VERSION ""

NS_ :

BS_:

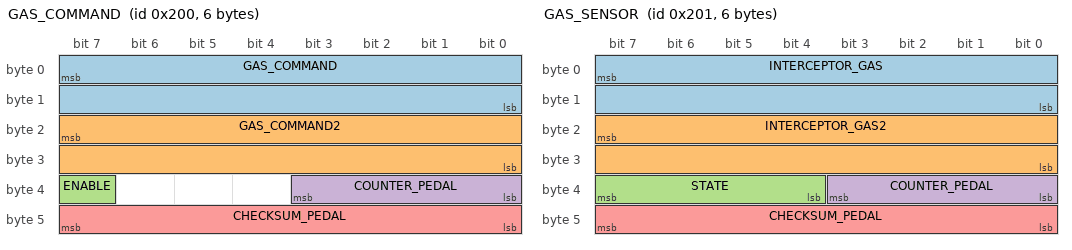
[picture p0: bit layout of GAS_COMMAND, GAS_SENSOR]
BO_ 512 GAS_COMMAND: 6 EON
 SG_ GAS_COMMAND : 7|16@0+ (0.253984064,-83.3) [0|1] "" INTERCEPTOR
 SG_ GAS_COMMAND2 : 23|16@0+ (0.126992032,-83.3) [0|1] "" INTERCEPTOR
 SG_ ENABLE : 39|1@0+ (1,0) [0|1] "" INTERCEPTOR
 SG_ COUNTER_PEDAL : 35|4@0+ (1,0) [0|15] "" INTERCEPTOR
 SG_ CHECKSUM_PEDAL : 47|8@0+ (1,0) [0|255] "" INTERCEPTOR

BO_ 513 GAS_SENSOR: 6 INTERCEPTOR
 SG_ INTERCEPTOR_GAS : 7|16@0+ (1,0) [0|1] "" EON
 SG_ INTERCEPTOR_GAS2 : 23|16@0+ (1,0) [0|1] "" EON
 SG_ STATE : 39|4@0+ (1,0) [0|15] "" EON
 SG_ COUNTER_PEDAL : 35|4@0+ (1,0) [0|15] "" EON
 SG_ CHECKSUM_PEDAL : 47|8@0+ (1,0) [0|255] "" EON

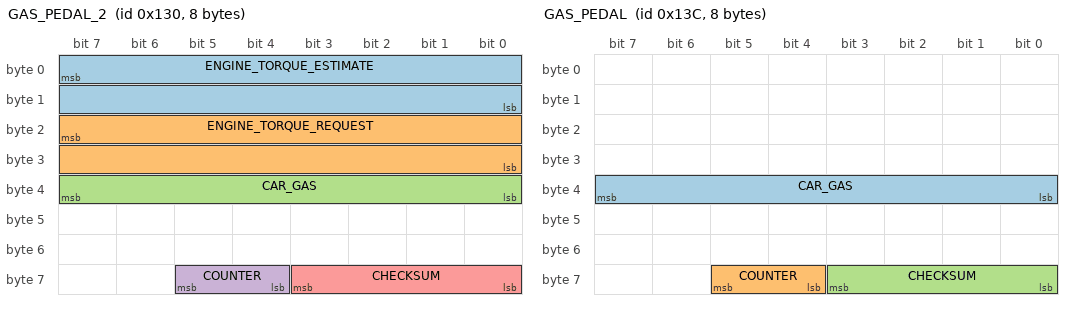
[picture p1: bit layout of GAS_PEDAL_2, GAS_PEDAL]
BO_ 304 GAS_PEDAL_2: 8 PCM
 SG_ ENGINE_TORQUE_ESTIMATE : 7|16@0- (1,0) [-1000|1000] "Nm" EON
 SG_ ENGINE_TORQUE_REQUEST : 23|16@0- (1,0) [-1000|1000] "Nm" EON
 SG_ CAR_GAS : 39|8@0+ (1,0) [0|255] "" EON
 SG_ COUNTER : 61|2@0+ (1,0) [0|3] "" EON
 SG_ CHECKSUM : 59|4@0+ (1,0) [0|15] "" EON

BO_ 316 GAS_PEDAL: 8 PCM
 SG_ CAR_GAS : 39|8@0+ (1,0) [0|255] "" EON
 SG_ COUNTER : 61|2@0+ (1,0) [0|3] "" EON
 SG_ CHECKSUM : 59|4@0+ (1,0) [0|15] "" EON

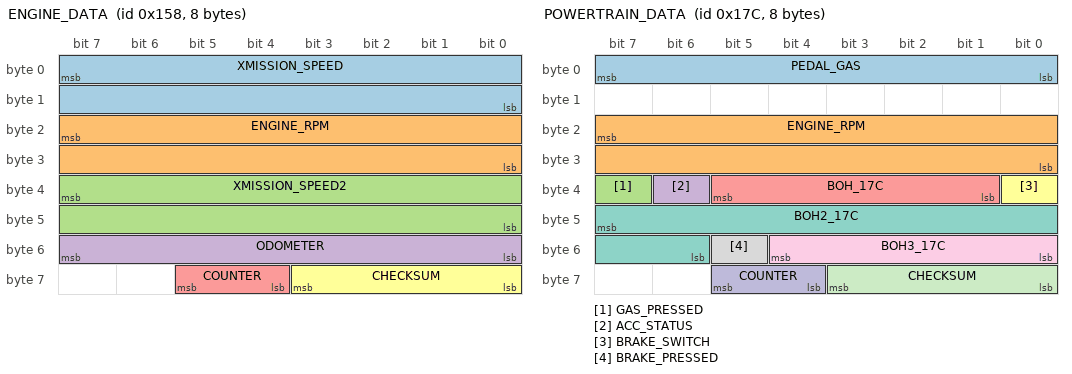
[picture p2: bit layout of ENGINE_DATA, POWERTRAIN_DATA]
BO_ 344 ENGINE_DATA: 8 PCM
 SG_ XMISSION_SPEED : 7|16@0+ (0.01,0) [0|250] "kph" EON
 SG_ ENGINE_RPM : 23|16@0+ (1,0) [0|15000] "rpm" EON
 SG_ XMISSION_SPEED2 : 39|16@0+ (0.01,0) [0|250] "kph" EON
 SG_ ODOMETER : 55|8@0+ (10,0) [0|2550] "m" XXX
 SG_ COUNTER : 61|2@0+ (1,0) [0|3] "" EON
 SG_ CHECKSUM : 59|4@0+ (1,0) [0|15] "" EON

BO_ 380 POWERTRAIN_DATA: 8 PCM
 SG_ PEDAL_GAS : 7|8@0+ (1,0) [0|255] "" EON
 SG_ ENGINE_RPM : 23|16@0+ (1,0) [0|15000] "rpm" EON
 SG_ GAS_PRESSED : 39|1@0+ (1,0) [0|1] "" EON
 SG_ ACC_STATUS : 38|1@0+ (1,0) [0|1] "" EON
 SG_ BOH_17C : 37|5@0+ (1,0) [0|1] "" EON
 SG_ BRAKE_SWITCH : 32|1@0+ (1,0) [0|1] "" EON
 SG_ BOH2_17C : 47|10@0+ (1,0) [0|1] "" EON
 SG_ BRAKE_PRESSED : 53|1@0+ (1,0) [0|1] "" EON
 SG_ BOH3_17C : 52|5@0+ (1,0) [0|1] "" EON
 SG_ COUNTER : 61|2@0+ (1,0) [0|3] "" EON
 SG_ CHECKSUM : 59|4@0+ (1,0) [0|15] "" EON

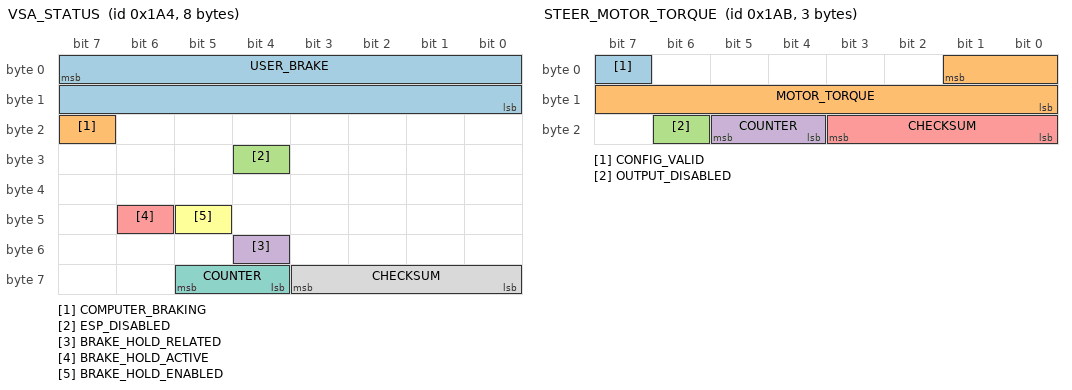
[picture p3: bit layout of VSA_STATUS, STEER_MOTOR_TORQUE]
BO_ 420 VSA_STATUS: 8 VSA
 SG_ USER_BRAKE : 7|16@0+ (0.015625,-1.609375) [0|1000] "" EON
 SG_ COMPUTER_BRAKING : 23|1@0+ (1,0) [0|1] "" EON
 SG_ ESP_DISABLED : 28|1@0+ (1,0) [0|1] "" EON
 SG_ BRAKE_HOLD_RELATED : 52|1@0+ (1,0) [0|1] "" XXX
 SG_ BRAKE_HOLD_ACTIVE : 46|1@0+ (1,0) [0|1] "" EON
 SG_ BRAKE_HOLD_ENABLED : 45|1@0+ (1,0) [0|1] "" EON
 SG_ COUNTER : 61|2@0+ (1,0) [0|3] "" EON
 SG_ CHECKSUM : 59|4@0+ (1,0) [0|15] "" EON

BO_ 427 STEER_MOTOR_TORQUE: 3 EPS
 SG_ CONFIG_VALID : 7|1@0+ (1,0) [0|1] "" EON
 SG_ MOTOR_TORQUE : 1|10@0+ (1,0) [0|256] "" EON
 SG_ OUTPUT_DISABLED : 22|1@0+ (1,0) [0|1] "" EON
 SG_ COUNTER : 21|2@0+ (1,0) [0|3] "" EON
 SG_ CHECKSUM : 19|4@0+ (1,0) [0|15] "" EON

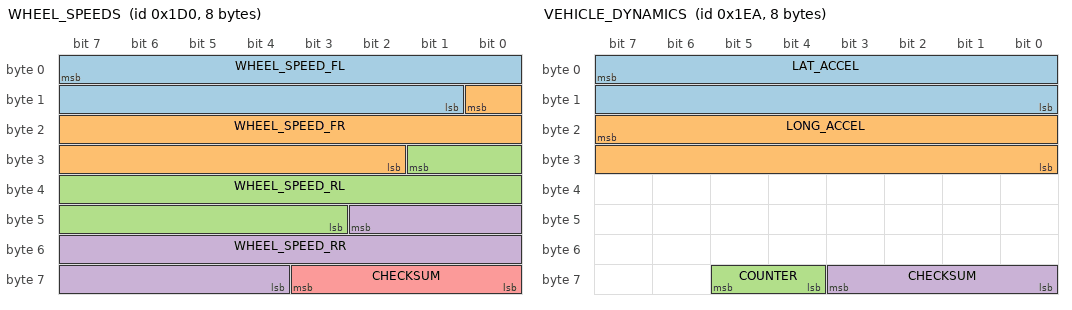
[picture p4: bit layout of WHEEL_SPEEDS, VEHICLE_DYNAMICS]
BO_ 464 WHEEL_SPEEDS: 8 VSA
 SG_ WHEEL_SPEED_FL : 7|15@0+ (0.01,0) [0|250] "kph" EON
 SG_ WHEEL_SPEED_FR : 8|15@0+ (0.01,0) [0|250] "kph" EON
 SG_ WHEEL_SPEED_RL : 25|15@0+ (0.01,0) [0|250] "kph" EON
 SG_ WHEEL_SPEED_RR : 42|15@0+ (0.01,0) [0|250] "kph" EON
 SG_ CHECKSUM : 59|4@0+ (1,0) [0|3] "" EON

BO_ 490 VEHICLE_DYNAMICS: 8 VSA
 SG_ LAT_ACCEL : 7|16@0- (0.0015,0) [-20|20] "m/s2" EON
 SG_ LONG_ACCEL : 23|16@0- (0.0015,0) [-20|20] "m/s2" EON
 SG_ COUNTER : 61|2@0+ (1,0) [0|3] "" EON
 SG_ CHECKSUM : 59|4@0+ (1,0) [0|3] "" EON

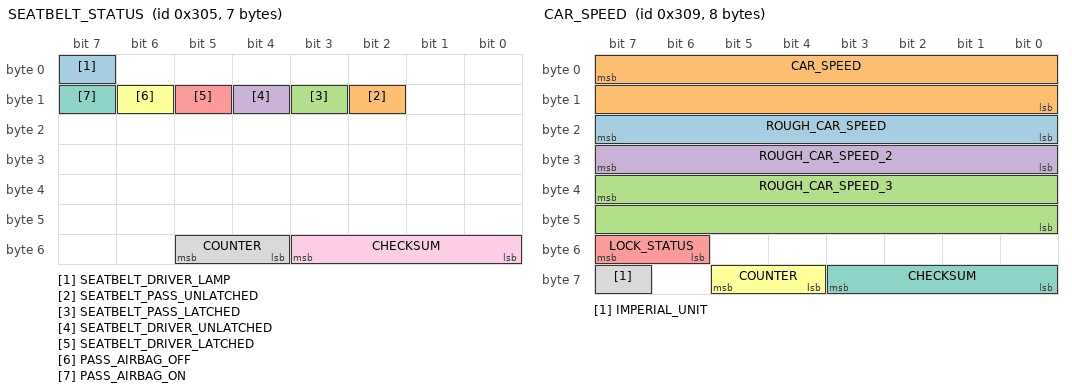
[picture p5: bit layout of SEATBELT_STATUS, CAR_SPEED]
BO_ 773 SEATBELT_STATUS: 7 BDY
 SG_ SEATBELT_DRIVER_LAMP : 7|1@0+ (1,0) [0|1] "" EON
 SG_ SEATBELT_PASS_UNLATCHED : 10|1@0+ (1,0) [0|1] "" EON
 SG_ SEATBELT_PASS_LATCHED : 11|1@0+ (1,0) [0|1] "" EON
 SG_ SEATBELT_DRIVER_UNLATCHED : 12|1@0+ (1,0) [0|1] "" EON
 SG_ SEATBELT_DRIVER_LATCHED : 13|1@0+ (1,0) [0|1] "" EON
 SG_ PASS_AIRBAG_OFF : 14|1@0+ (1,0) [0|1] "" EON
 SG_ PASS_AIRBAG_ON : 15|1@0+ (1,0) [0|1] "" EON
 SG_ COUNTER : 53|2@0+ (1,0) [0|3] "" EON
 SG_ CHECKSUM : 51|4@0+ (1,0) [0|3] "" EON

BO_ 777 CAR_SPEED: 8 PCM
 SG_ ROUGH_CAR_SPEED : 23|8@0+ (1,0) [0|255] "mph" XXX
 SG_ CAR_SPEED : 7|16@0+ (0.01,0) [0|65535] "kph" XXX
 SG_ ROUGH_CAR_SPEED_3 : 39|16@0+ (0.01,0) [0|65535] "kph" XXX
 SG_ ROUGH_CAR_SPEED_2 : 31|8@0+ (1,0) [0|255] "mph" XXX
 SG_ LOCK_STATUS : 55|2@0+ (1,0) [0|255] "" XXX
 SG_ COUNTER : 61|2@0+ (1,0) [0|3] "" XXX
 SG_ CHECKSUM : 59|4@0+ (1,0) [0|15] "" XXX
 SG_ IMPERIAL_UNIT : 63|1@0+ (1,0) [0|1] "" XXX

BO_ 780 ACC_HUD: 8 ADAS
 SG_ PCM_SPEED : 7|16@0+ (0.01,0) [0|250] "kph" BDY
 SG_ PCM_GAS : 23|8@0+ (1,0) [0|127] "" BDY
 SG_ CRUISE_SPEED : 31|8@0+ (1,0) [0|255] "kph" BDY
 SG_ DTC_MODE : 39|1@0+ (1,0) [0|1] "" BDY
 SG_ BOH : 38|1@0+ (1,0) [0|1] "" BDY
 SG_ ACC_PROBLEM : 37|1@0+ (1,0) [0|1] "" BDY
 SG_ FCM_OFF : 35|1@0+ (1,0) [0|1] "" BDY
 SG_ FCM_OFF_2 : 36|1@0+ (1,0) [0|1] "" BDY
 SG_ FCM_PROBLEM : 34|1@0+ (1,0) [0|1] "" BDY
 SG_ RADAR_OBSTRUCTED : 33|1@0+ (1,0) [0|1] "" BDY
 SG_ ENABLE_MINI_CAR : 32|1@0+ (1,0) [0|1] "" BDY
 SG_ HUD_DISTANCE : 47|2@0+ (1,0) [0|3] "" BDY
 SG_ HUD_LEAD : 45|2@0+ (1,0) [0|3] "" BDY
 SG_ BOH_3 : 43|1@0+ (1,0) [0|3] "" BDY
 SG_ BOH_4 : 42|1@0+ (1,0) [0|3] "" BDY
 SG_ BOH_5 : 41|1@0+ (1,0) [0|3] "" BDY
 SG_ CRUISE_CONTROL_LABEL : 40|1@0+ (1,0) [0|3] "" BDY
 SG_ SET_ME_X01_2 : 55|1@0+ (1,0) [0|1] "" BDY
 SG_ IMPERIAL_UNIT : 54|1@0+ (1,0) [0|1] "" BDY
 SG_ ACC_ON : 52|1@0+ (1,0) [0|1] "" BDY
 SG_ CHIME : 51|3@0+ (1,0) [0|1] "" BDY
 SG_ SET_ME_X01 : 48|1@0+ (1,0) [0|1] "" BDY
 SG_ ICONS : 63|2@0+ (1,0) [0|1] "" BDY
 SG_ COUNTER : 61|2@0+ (1,0) [0|3] "" BDY
 SG_ CHECKSUM : 59|4@0+ (1,0) [0|3] "" BDY

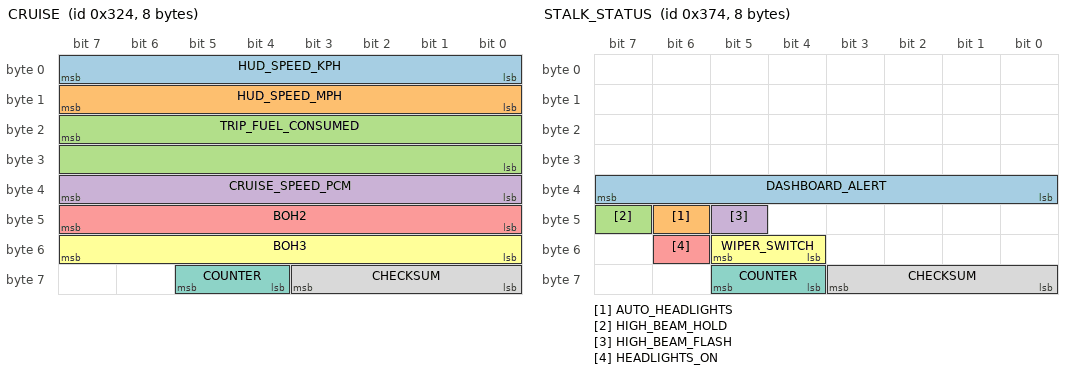
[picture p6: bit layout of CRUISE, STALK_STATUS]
BO_ 804 CRUISE: 8 PCM
 SG_ HUD_SPEED_KPH : 7|8@0+ (1,0) [0|255] "kph" EON
 SG_ HUD_SPEED_MPH : 15|8@0+ (1,0) [0|255] "mph" EON
 SG_ TRIP_FUEL_CONSUMED : 23|16@0+ (1,0) [0|255] "" EON
 SG_ CRUISE_SPEED_PCM : 39|8@0+ (1,0) [0|255] "" EON
 SG_ BOH2 : 47|8@0- (1,0) [0|255] "" EON
 SG_ BOH3 : 55|8@0+ (1,0) [0|255] "" EON
 SG_ COUNTER : 61|2@0+ (1,0) [0|3] "" EON
 SG_ CHECKSUM : 59|4@0+ (1,0) [0|15] "" EON

BO_ 884 STALK_STATUS: 8 XXX
 SG_ DASHBOARD_ALERT : 39|8@0+ (1,0) [0|255] "" EON
 SG_ AUTO_HEADLIGHTS : 46|1@0+ (1,0) [0|1] "" EON
 SG_ HIGH_BEAM_HOLD : 47|1@0+ (1,0) [0|1] "" EON
 SG_ HIGH_BEAM_FLASH : 45|1@0+ (1,0) [0|1] "" EON
 SG_ HEADLIGHTS_ON : 54|1@0+ (1,0) [0|1] "" EON
 SG_ WIPER_SWITCH : 53|2@0+ (1,0) [0|3] "" XXX
 SG_ COUNTER : 61|2@0+ (1,0) [0|3] "" EON
 SG_ CHECKSUM : 59|4@0+ (1,0) [0|15] "" EON

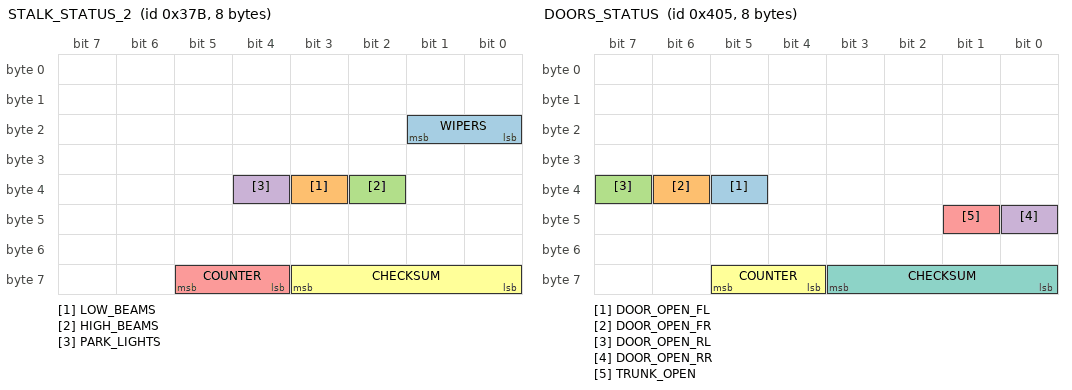
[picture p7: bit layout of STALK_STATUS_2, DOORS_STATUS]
BO_ 891 STALK_STATUS_2: 8 XXX
 SG_ WIPERS : 17|2@0+ (1,0) [0|3] "" EON
 SG_ LOW_BEAMS : 35|1@0+ (1,0) [0|1] "" XXX
 SG_ HIGH_BEAMS : 34|1@0+ (1,0) [0|1] "" XXX
 SG_ PARK_LIGHTS : 36|1@0+ (1,0) [0|1] "" XXX
 SG_ COUNTER : 61|2@0+ (1,0) [0|3] "" EON
 SG_ CHECKSUM : 59|4@0+ (1,0) [0|15] "" EON

BO_ 1029 DOORS_STATUS: 8 BDY
 SG_ DOOR_OPEN_FL : 37|1@0+ (1,0) [0|1] "" EON
 SG_ DOOR_OPEN_FR : 38|1@0+ (1,0) [0|1] "" EON
 SG_ DOOR_OPEN_RL : 39|1@0+ (1,0) [0|1] "" EON
 SG_ DOOR_OPEN_RR : 40|1@0+ (1,0) [0|1] "" EON
 SG_ TRUNK_OPEN : 41|1@0+ (1,0) [0|1] "" EON
 SG_ COUNTER : 61|2@0+ (1,0) [0|3] "" EON
 SG_ CHECKSUM : 59|4@0+ (1,0) [0|15] "" EON

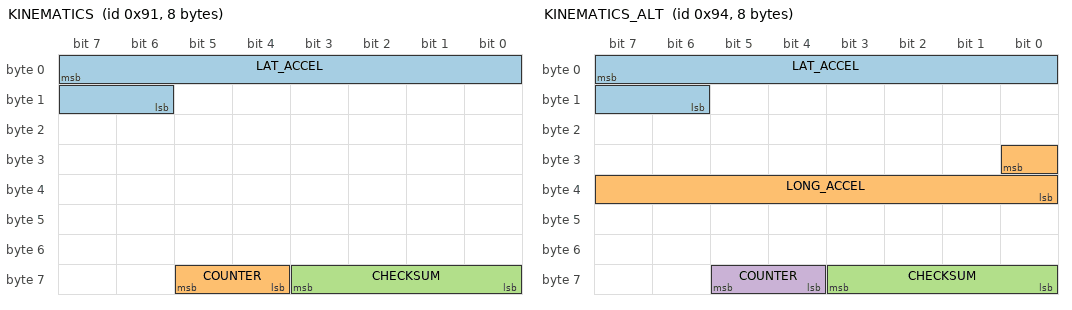
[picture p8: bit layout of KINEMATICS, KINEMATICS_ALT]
BO_ 145 KINEMATICS: 8 XXX
 SG_ LAT_ACCEL : 7|10@0+ (0.02,-512) [-20|20] "m/s2" EON
 SG_ COUNTER : 61|2@0+ (1,0) [0|3] "" EON
 SG_ CHECKSUM : 59|4@0+ (1,0) [0|3] "" EON

BO_ 148 KINEMATICS_ALT: 8 XXX
 SG_ LAT_ACCEL : 7|10@0+ (0.02,-512) [-20|20] "m/s2" EON
 SG_ LONG_ACCEL : 24|9@0- (-0.02,0) [-20|20] "m/s2" EON
 SG_ CHECKSUM : 59|4@0+ (1,0) [0|3] "" EON
 SG_ COUNTER : 61|2@0+ (1,0) [0|3] "" EON

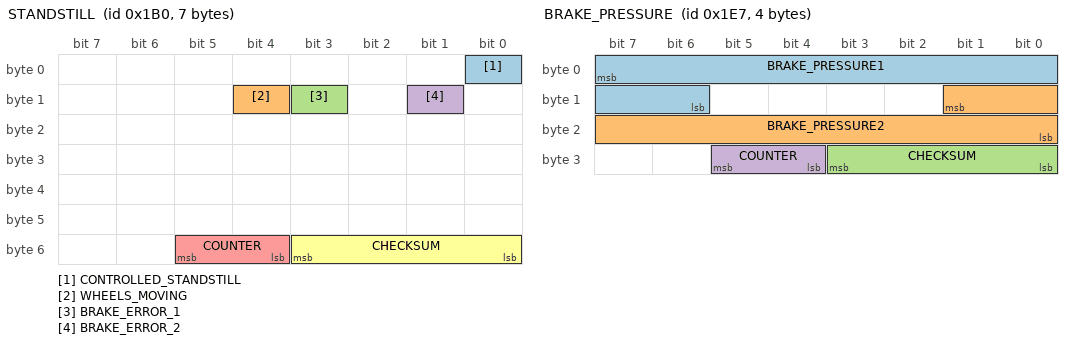
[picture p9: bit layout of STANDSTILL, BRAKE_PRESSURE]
BO_ 432 STANDSTILL: 7 VSA
 SG_ CONTROLLED_STANDSTILL : 0|1@0+ (1,0) [0|1] "" EON
 SG_ WHEELS_MOVING : 12|1@0+ (1,0) [0|1] "" EON
 SG_ BRAKE_ERROR_1 : 11|1@0+ (1,0) [0|1] "" EON
 SG_ BRAKE_ERROR_2 : 9|1@0+ (1,0) [0|1] "" EON
 SG_ COUNTER : 53|2@0+ (1,0) [0|3] "" EON
 SG_ CHECKSUM : 51|4@0+ (1,0) [0|3] "" EON

BO_ 487 BRAKE_PRESSURE: 4 VSA
 SG_ BRAKE_PRESSURE1 : 7|10@0+ (0.015625,-103) [0|1000] "" EON
 SG_ BRAKE_PRESSURE2 : 9|10@0+ (0.015625,-103) [0|1000] "" EON
 SG_ CHECKSUM : 27|4@0+ (1,0) [0|15] "" EON
 SG_ COUNTER : 29|2@0+ (1,0) [0|3] "" EON

BO_ 506 BRAKE_COMMAND: 8 ADAS
 SG_ COMPUTER_BRAKE : 7|10@0+ (1,0) [0|1] "" EBCM
 SG_ BRAKE_PUMP_REQUEST : 8|1@0+ (1,0) [0|1] "" EBCM
 SG_ BRAKE_PUMP_REQUEST_ALT : 11|1@0+ (1,0) [0|1] "" EBCM
 SG_ SET_ME_X00 : 23|3@0+ (1,0) [0|1] "" EBCM
 SG_ CRUISE_OVERRIDE : 20|1@0+ (1,0) [0|1] "" EBCM
 SG_ SET_ME_X00_2 : 19|1@0+ (1,0) [0|1] "" EBCM
 SG_ CRUISE_FAULT_CMD : 18|1@0+ (1,0) [0|1] "" EBCM
 SG_ CRUISE_CANCEL_CMD : 17|1@0+ (1,0) [0|1] "" EBCM
 SG_ COMPUTER_BRAKE_REQUEST : 16|1@0+ (1,0) [0|1] "" EBCM
 SG_ SET_ME_1 : 31|1@0+ (1,0) [0|1] "" EBCM
 SG_ AEB_REQ_1 : 29|1@0+ (1,0) [0|1] "" XXX
 SG_ AEB_REQ_2 : 26|3@0+ (1,0) [0|7] "" XXX
 SG_ BRAKE_LIGHTS : 39|1@0+ (1,0) [0|1] "" EBCM
 SG_ CRUISE_STATES : 38|7@0+ (1,0) [0|1] "" EBCM
 SG_ CHIME : 47|3@0+ (1,0) [0|7] "" EBCM
 SG_ SET_ME_X00_3 : 44|1@0+ (1,0) [0|1] "" EBCM
 SG_ FCW : 43|2@0+ (1,0) [0|3] "" EBCM
 SG_ AEB_STATUS : 41|2@0+ (1,0) [0|3] "" XXX
 SG_ COMPUTER_BRAKE_ALT : 55|10@0+ (1,0) [0|0] "" EBCM
 SG_ COUNTER : 61|2@0+ (1,0) [0|3] "" EBCM
 SG_ CHECKSUM : 59|4@0+ (1,0) [0|15] "" EBCM

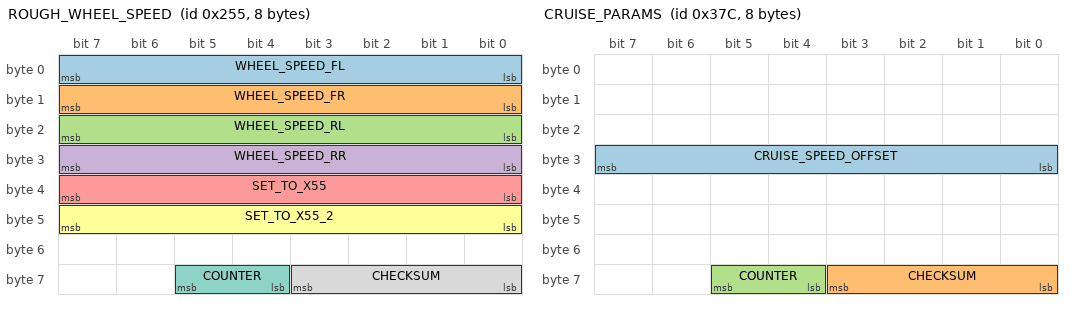
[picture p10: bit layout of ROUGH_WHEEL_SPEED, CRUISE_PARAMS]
BO_ 597 ROUGH_WHEEL_SPEED: 8 VSA
 SG_ WHEEL_SPEED_FL : 7|8@0+ (1,0) [0|255] "mph" EON
 SG_ WHEEL_SPEED_FR : 15|8@0+ (1,0) [0|255] "mph" EON
 SG_ WHEEL_SPEED_RL : 23|8@0+ (1,0) [0|255] "mph" EON
 SG_ WHEEL_SPEED_RR : 31|8@0+ (1,0) [0|255] "mph" EON
 SG_ SET_TO_X55 : 39|8@0+ (1,0) [0|255] "" EON
 SG_ SET_TO_X55_2 : 47|8@0+ (1,0) [0|255] "" EON
 SG_ COUNTER : 61|2@0+ (1,0) [0|3] "" EON
 SG_ CHECKSUM : 59|4@0+ (1,0) [0|15] "" EON

BO_ 829 LKAS_HUD: 5 ADAS
 SG_ CAM_TEMP_HIGH : 7|1@0+ (1,0) [0|255] "" BDY
 SG_ SET_ME_X41 : 6|7@0+ (1,0) [0|127] "" BDY
 SG_ BOH : 6|7@0+ (1,0) [0|127] "" BDY
 SG_ DASHED_LANES : 14|1@0+ (1,0) [0|1] "" BDY
 SG_ DTC : 13|1@0+ (1,0) [0|1] "" BDY
 SG_ LKAS_PROBLEM : 12|1@0+ (1,0) [0|1] "" BDY
 SG_ LKAS_OFF : 11|1@0+ (1,0) [0|1] "" BDY
 SG_ SOLID_LANES : 10|1@0+ (1,0) [0|1] "" BDY
 SG_ LDW_RIGHT : 9|1@0+ (1,0) [0|1] "" BDY
 SG_ STEERING_REQUIRED : 8|1@0+ (1,0) [0|1] "" BDY
 SG_ BOH_2 : 23|2@0+ (1,0) [0|4] "" BDY
 SG_ LDW_PROBLEM : 21|1@0+ (1,0) [0|1] "" BDY
 SG_ BEEP : 17|2@0+ (1,0) [0|1] "" BDY
 SG_ LDW_ON : 28|1@0+ (1,0) [0|1] "" BDY
 SG_ LDW_OFF : 27|1@0+ (1,0) [0|1] "" BDY
 SG_ CLEAN_WINDSHIELD : 26|1@0+ (1,0) [0|1] "" BDY
 SG_ SET_ME_X48 : 31|8@0+ (1,0) [0|255] "" BDY
 SG_ COUNTER : 37|2@0+ (1,0) [0|3] "" BDY
 SG_ CHECKSUM : 35|4@0+ (1,0) [0|15] "" BDY

BO_ 892 CRUISE_PARAMS: 8 PCM
 SG_ CRUISE_SPEED_OFFSET : 31|8@0- (0.1,0) [-128|127] "kph" EON
 SG_ CHECKSUM : 59|4@0+ (1,0) [0|3] "" EON
 SG_ COUNTER : 61|2@0+ (1,0) [0|3] "" EON

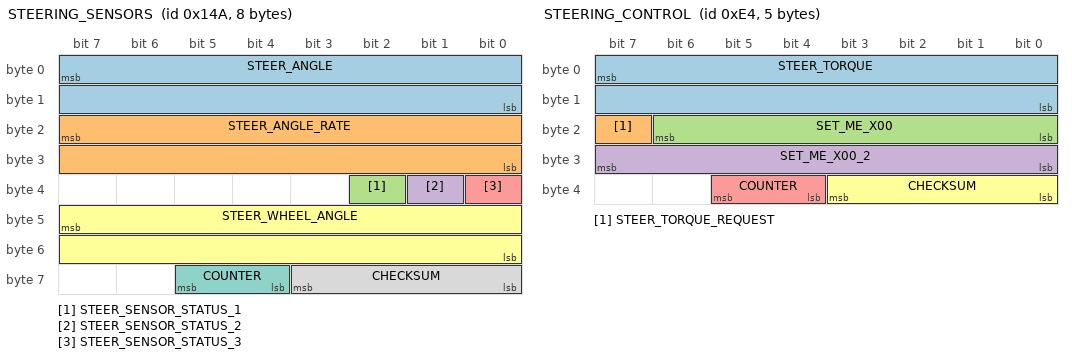
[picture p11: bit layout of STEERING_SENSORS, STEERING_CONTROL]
BO_ 330 STEERING_SENSORS: 8 EPS
 SG_ STEER_ANGLE : 7|16@0- (-0.1,0) [-500|500] "deg" EON
 SG_ STEER_ANGLE_RATE : 23|16@0- (-1,0) [-3000|3000] "deg/s" EON
 SG_ STEER_SENSOR_STATUS_1 : 34|1@0+ (1,0) [0|1] "" EON
 SG_ STEER_SENSOR_STATUS_2 : 33|1@0+ (1,0) [0|1] "" EON
 SG_ STEER_SENSOR_STATUS_3 : 32|1@0+ (1,0) [0|1] "" EON
 SG_ STEER_WHEEL_ANGLE : 47|16@0- (-0.1,0) [-500|500] "deg" EON
 SG_ COUNTER : 61|2@0+ (1,0) [0|3] "" EON
 SG_ CHECKSUM : 59|4@0+ (1,0) [0|15] "" EON

BO_ 228 STEERING_CONTROL: 5 ADAS
 SG_ STEER_TORQUE : 7|16@0- (1,0) [-3840|3840] "" EPS
 SG_ STEER_TORQUE_REQUEST : 23|1@0+ (1,0) [0|1] "" EPS
 SG_ SET_ME_X00 : 22|7@0+ (1,0) [0|127] "" EPS
 SG_ SET_ME_X00_2 : 31|8@0+ (1,0) [0|0] "" EPS
 SG_ COUNTER : 37|2@0+ (1,0) [0|3] "" EPS
 SG_ CHECKSUM : 35|4@0+ (1,0) [0|15] "" EPS

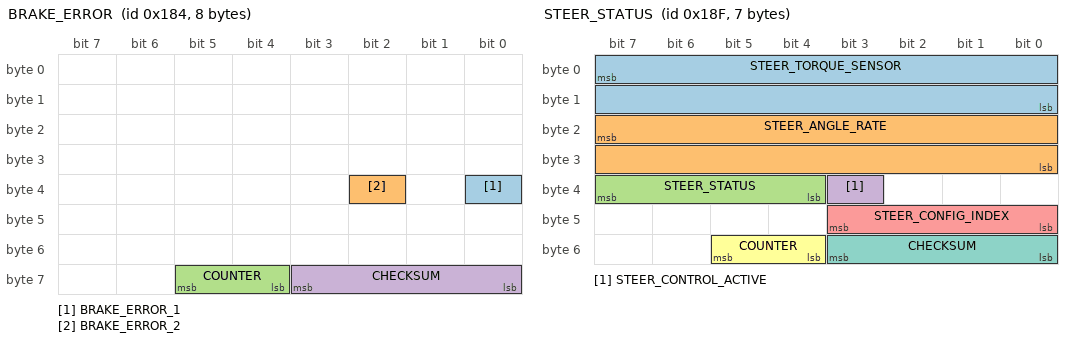
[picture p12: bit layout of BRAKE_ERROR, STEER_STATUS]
BO_ 388 BRAKE_ERROR: 8 XXX
 SG_ BRAKE_ERROR_1 : 32|1@0+ (1,0) [0|1] "" EON
 SG_ BRAKE_ERROR_2 : 34|1@0+ (1,0) [0|1] "" EON
 SG_ COUNTER : 61|2@0+ (1,0) [0|3] "" EON
 SG_ CHECKSUM : 59|4@0+ (1,0) [0|3] "" EON

BO_ 399 STEER_STATUS: 7 EPS
 SG_ STEER_TORQUE_SENSOR : 7|16@0- (-1,0) [-31000|31000] "tbd" EON
 SG_ STEER_ANGLE_RATE : 23|16@0- (-0.1,0) [-31000|31000] "deg/s" EON
 SG_ STEER_STATUS : 39|4@0+ (1,0) [0|15] "" EON
 SG_ STEER_CONTROL_ACTIVE : 35|1@0+ (1,0) [0|1] "" EON
 SG_ STEER_CONFIG_INDEX : 43|4@0+ (1,0) [0|15] "" EON
 SG_ COUNTER : 53|2@0+ (1,0) [0|3] "" EON
 SG_ CHECKSUM : 51|4@0+ (1,0) [0|3] "" EON

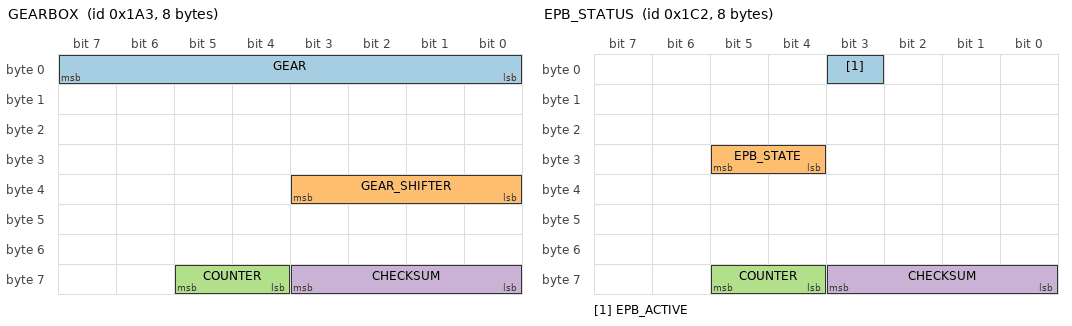
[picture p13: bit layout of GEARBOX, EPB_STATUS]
BO_ 419 GEARBOX: 8 PCM
 SG_ GEAR : 7|8@0+ (1,0) [0|256] "" EON
 SG_ GEAR_SHIFTER : 35|4@0+ (1,0) [0|15] "" EON
 SG_ COUNTER : 61|2@0+ (1,0) [0|3] "" EON
 SG_ CHECKSUM : 59|4@0+ (1,0) [0|3] "" EON

BO_ 450 EPB_STATUS: 8 EPB
 SG_ EPB_ACTIVE : 3|1@0+ (1,0) [0|1] "" EON
 SG_ EPB_STATE : 29|2@0+ (1,0) [0|3] "" EON
 SG_ COUNTER : 61|2@0+ (1,0) [0|3] "" EON
 SG_ CHECKSUM : 59|4@0+ (1,0) [0|3] "" EON

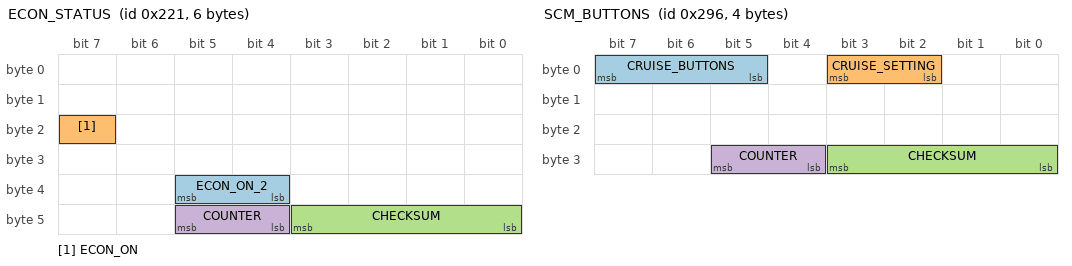
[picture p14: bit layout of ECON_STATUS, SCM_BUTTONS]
BO_ 545 ECON_STATUS: 6 XXX
 SG_ ECON_ON_2 : 37|2@0+ (1,0) [0|3] "" EON
 SG_ ECON_ON : 23|1@0+ (1,0) [0|1] "" EON
 SG_ CHECKSUM : 43|4@0+ (1,0) [0|3] "" EON
 SG_ COUNTER : 45|2@0+ (1,0) [0|3] "" EON

BO_ 662 SCM_BUTTONS: 4 SCM
 SG_ CRUISE_BUTTONS : 7|3@0+ (1,0) [0|7] "" EON
 SG_ CRUISE_SETTING : 3|2@0+ (1,0) [0|3] "" EON
 SG_ CHECKSUM : 27|4@0+ (1,0) [0|3] "" EON
 SG_ COUNTER : 29|2@0+ (1,0) [0|3] "" EON

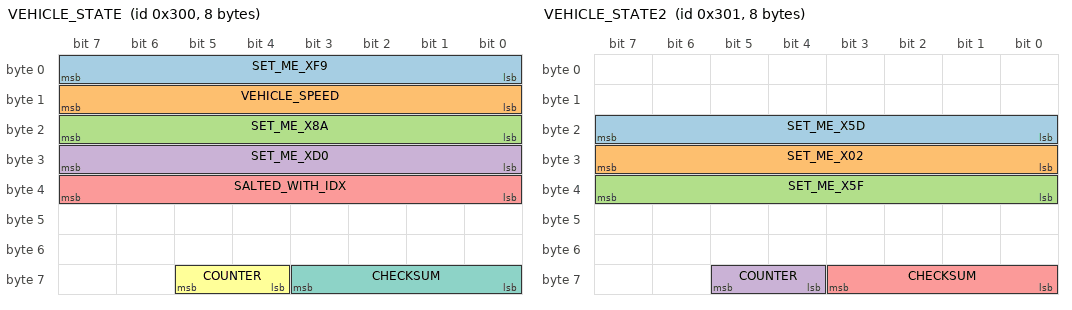
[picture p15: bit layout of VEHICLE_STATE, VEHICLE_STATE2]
BO_ 768 VEHICLE_STATE: 8 ADAS
 SG_ SET_ME_XF9 : 7|8@0+ (1,0) [0|255] "" Vector__XXX
 SG_ VEHICLE_SPEED : 15|8@0+ (1,0) [0|255] "kph" Vector__XXX
 SG_ SET_ME_X8A : 23|8@0+ (1,0) [0|255] "" XXX
 SG_ SET_ME_XD0 : 31|8@0+ (1,0) [0|255] "" XXX
 SG_ SALTED_WITH_IDX : 39|8@0+ (1,0) [0|255] "" XXX
 SG_ COUNTER : 61|2@0+ (1,0) [0|3] "" XXX
 SG_ CHECKSUM : 59|4@0+ (1,0) [0|15] "" XXX

BO_ 769 VEHICLE_STATE2: 8 ADAS
 SG_ SET_ME_X5D : 23|8@0+ (1,0) [0|255] "" XXX
 SG_ SET_ME_X02 : 31|8@0+ (1,0) [0|255] "" XXX
 SG_ SET_ME_X5F : 39|8@0+ (1,0) [0|255] "" XXX
 SG_ COUNTER : 61|2@0+ (1,0) [0|3] "" XXX
 SG_ CHECKSUM : 59|4@0+ (1,0) [0|15] "" XXX

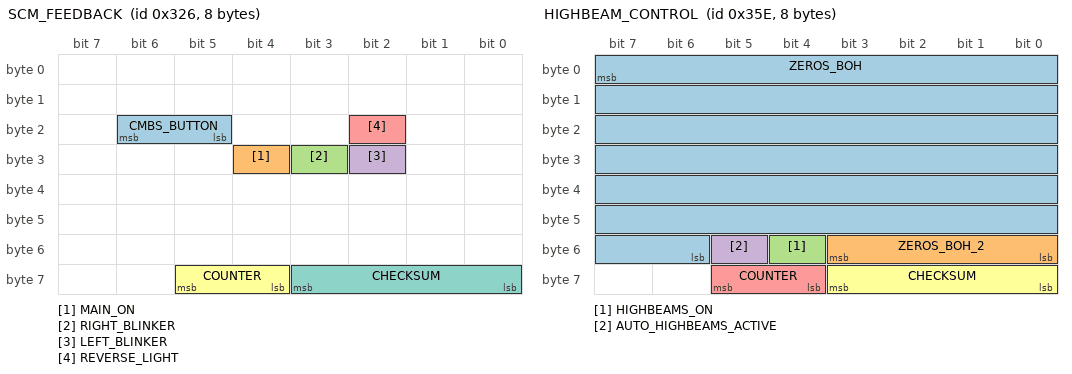
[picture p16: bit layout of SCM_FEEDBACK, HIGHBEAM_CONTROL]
BO_ 806 SCM_FEEDBACK: 8 SCM
 SG_ CMBS_BUTTON : 22|2@0+ (1,0) [0|3] "" EON
 SG_ MAIN_ON : 28|1@0+ (1,0) [0|1] "" EON
 SG_ RIGHT_BLINKER : 27|1@0+ (1,0) [0|1] "" EON
 SG_ LEFT_BLINKER : 26|1@0+ (1,0) [0|1] "" EON
 SG_ REVERSE_LIGHT : 18|1@0+ (1,0) [0|1] "" EON
 SG_ COUNTER : 61|2@0+ (1,0) [0|3] "" EON
 SG_ CHECKSUM : 59|4@0+ (1,0) [0|15] "" EON

BO_ 862 HIGHBEAM_CONTROL: 8 ADAS
 SG_ ZEROS_BOH : 7|50@0+ (1,0) [0|127] "" BDY
 SG_ ZEROS_BOH_2 : 48|4@1+ (1,0) [0|15] "" XXX
 SG_ HIGHBEAMS_ON : 52|1@0+ (1,0) [0|1] "" XXX
 SG_ AUTO_HIGHBEAMS_ACTIVE : 53|1@0+ (1,0) [0|1] "" XXX
 SG_ COUNTER : 61|2@0+ (1,0) [0|3] "" XXX
 SG_ CHECKSUM : 59|4@0+ (1,0) [0|15] "" XXX

BO_ 927 RADAR_HUD: 8 ADAS
 SG_ ZEROS_BOH : 7|17@0+ (1,0) [0|127] "" BDY
 SG_ APPLY_BRAKES_FOR_CANC : 23|1@0+ (1,0) [0|15] "" BDY
 SG_ ZEROS_BOH2 : 31|8@0+ (1,0) [0|127] "" BDY
 SG_ RESUME_INSTRUCTION : 21|1@0+ (1,0) [0|15] "" BDY
 SG_ ACC_ALERTS : 20|5@0+ (1,0) [0|15] "" BDY
 SG_ LEAD_SPEED : 39|9@0+ (1,0) [0|127] "" BDY
 SG_ LEAD_STATE : 46|3@0+ (1,0) [0|127] "" BDY
 SG_ LEAD_DISTANCE : 43|5@0+ (1,0) [0|31] "" BDY
 SG_ ZEROS_BOH3 : 54|7@0+ (1,0) [0|127] "" BDY
 SG_ COUNTER : 61|2@0+ (1,0) [0|3] "" BDY
 SG_ CHECKSUM : 59|4@0+ (1,0) [0|15] "" BDY

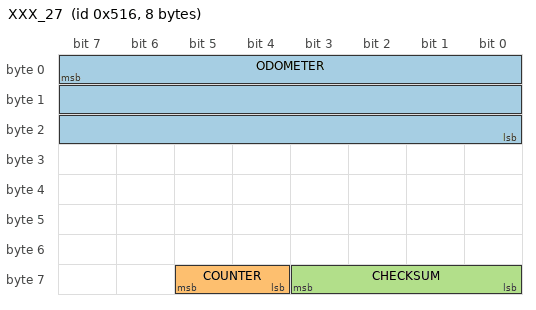
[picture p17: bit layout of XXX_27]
BO_ 1302 XXX_27: 8 XXX
 SG_ ODOMETER : 7|24@0+ (1,0) [0|16777215] "km" EON
 SG_ COUNTER : 61|2@0+ (1,0) [0|3] "" EON
 SG_ CHECKSUM : 59|4@0+ (1,0) [0|15] "" EON

CM_ "AUTOGENERATED FILE, DO NOT EDIT";

CM_ "Imported file _subaru_global.dbc starts here";
CM_ SG_ 64 Throttle_Combo "Throttle Cruise + Pedal";
CM_ SG_ 313 Brake_Lights "Driver or Cruise Brake on";
CM_ SG_ 544 Cruise_Brake_Lights "1 = switch on brake lights";
CM_ SG_ 544 Brake_Pressure "Winds down after cruise disabled. Also can be non-zero when likely preparing for AEB";
CM_ SG_ 544 Signal3 "Usually goes to 2 if AEB_Status is 4";
CM_ SG_ 544 AEB_Status "Occasionally is 4 instead of 8 while Brake_Pressure is non-zero, unsure why";
CM_ SG_ 801 PCB_Off "Pre-Collision Braking off";
CM_ SG_ 801 Brake_Lights "Driver or Cruise brake on";
CM_ SG_ 801 Cruise_State "0 = Normal, 1 = Hold+User Brake, 2 = Ready, 3 = Hold";
CM_ SG_ 801 Far_Distance "1=0-5m, 2=5-10m, 3=10-15m, 4=15-20m, 5=20-25m, 6=25-30m, 7=30-35m, 8=35-40m, 9=40-45m, 10=45-50m, 11=50-55m, 12=55-60m, 13=60-65m, 14=65-70m, 15=75m+";
CM_ SG_ 801 LKAS_State_Msg "1 = LKAS_Off_Sharp_Curve, 2 = Keep_Hands_On_Steering_wheel_disabled, 3 = LKAS_Off, 4 = LKAS_Off_Too_Slow, 5 = LKAS_Off_Too_Fast";
CM_ SG_ 801 Cruise_State_Msg "1 = Cruise_Off_Steep_Slope, 2 = Cruise_lvl1_eco, 3 = Cruise_lvl2_comfort, 4 = Cruise_off_empty_reason, 5 = Cruise_off, 6 = Cruise_Unable_to_set, 7 = Cruise_Unable_to_set_brakes_applied, 8 = Eyesight_not_ready, 9 = Cruise_lvl3_standard, 10 = Cruise_lvl4_dynamic, 11 = Cruise_Unable_to_set_steep_slope";
CM_ SG_ 801 Cruise_Soft_Disable "Eyesight soft disable (eg direct sunlight)";
CM_ SG_ 801 Cruise_Status_Msg "1 = Disabled_Bad_Visibility, 2 = Disabled_Check_Manual";
CM_ SG_ 802 LKAS_ACTIVE "Turns on the full LKAS dash display";
CM_ SG_ 802 LKAS_Alert_Msg "1 = Keep_Hands_On_Wheel, 6 = Pre_Collision_Braking, 7 = Keep_Hands_On_Wheel_Off";
CM_ SG_ 802 LKAS_Alert "1 = FCW_Cont_Beep, 2 = FCW_Repeated_Beep, 3 = Throttle_Management_Activated_Warning, 4 = Throttle_Management_Activated_Alert, 5 = Pre_Collision_Activated_Alert, 8 = Traffic_Light_Ahead, 9 = Apply_Brake_to_Hold Position, 11 = LDW_Right, 12 = LDW_Left, 13 = Stay_Alert, 14 = Lead_Vehicle_Start_Alert, 18 = Keep_Hands_On_Steering_Alert, 24 = Audio_Beep, 25 = Audio_Lead_Car_Change, 26 = Audio_ACC_Disengaged, 27 = Audio_LKAS_disabled, 28 = Audio_Ding_Ding, 30 = Audio_Repeated_Beep";
CM_ SG_ 802 LKAS_Left_Line_Visible "0 = Off, 1 = White, 2 = Green, 3 = Orange";
CM_ SG_ 802 LKAS_Dash_State "0 = Off, 1 = Ready, 2 = Active";
CM_ SG_ 802 LKAS_Right_Line_Visible "0 = Off, 1 = White, 2 = Green, 3 = Orange";
CM_ SG_ 912 UNITS "0 = Metric, 1 = Imperial";
CM_ SG_ 912 ICY_ROAD "1 = DASHLIGHT ON, 2 = WARNING, 3 = OFF";
CM_ "subaru_global_2020_hybrid.dbc starts here";

VAL_ 274 CUR_GR 1 "D" 2 "D" 3 "D" 4 "D" 5 "D" 6 "D" 7 "D" 8 "D" 14 "R" 0 "P";
VAL_ 871 CF_Lvr_IsgState 0 "enabled" 1 "activated" 2 "unknown" 3 "disabled";
VAL_ 871 CF_Lvr_Gear 12 "T" 5 "D" 8 "S" 6 "N" 7 "R" 0 "P";
VAL_ 882 Elect_Gear_Shifter 5 "D" 8 "S" 6 "N" 7 "R" 0 "P";
VAL_ 905 ACCMode 0 "off" 1 "enabled" 2 "driver_override" 3 "off_maybe_fault" 4 "cancelled";
VAL_ 909 CF_VSM_Warn 2 "FCW" 3 "AEB";
VAL_ 916 ACCEnable 0 "SCC ready" 1 "SCC temp fault" 2 "SCC permanent fault" 3 "SCC permanent fault, communication issue";
VAL_ 1056 SCCInfoDisplay 0 "No Message" 2 "Cruise Control" 3 "Lost Lead" 4 "Standstill";
VAL_ 1057 ACCMode 0 "off" 1 "enabled" 2 "driver_override" 3 "off_maybe_fault";
VAL_ 1157 HDA_Icon_State 0 "no_hda" 1 "white_hda" 2 "green_hda";
VAL_ 1157 LFA_SysWarning 0 "no_message" 1 "switching_to_hda" 2 "switching_to_scc" 3 "lfa_error" 4 "check_hda" 5 "keep_hands_on_wheel_orange" 6 "keep_hands_on_wheel_red";
VAL_ 1157 LFA_Icon_State 0 "no_wheel" 1 "white_wheel" 2 "green_wheel" 3 "green_wheel_blink";
VAL_ 1157 HDA_SysWarning 0 "no_message" 1 "driving_convenience_systems_cancelled" 2 "highway_drive_assist_system_cancelled";
